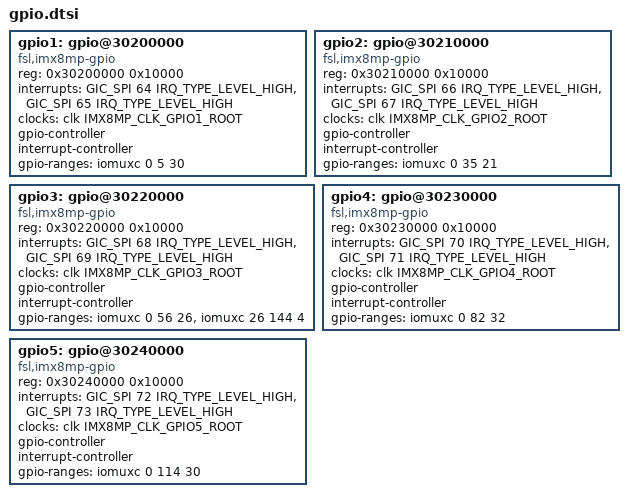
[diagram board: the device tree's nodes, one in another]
			gpio1: gpio@30200000 {
				compatible = "fsl,imx8mp-gpio", "fsl,imx35-gpio";
				reg = <0x30200000 0x10000>;
				interrupts = <GIC_SPI 64 IRQ_TYPE_LEVEL_HIGH>,
					     <GIC_SPI 65 IRQ_TYPE_LEVEL_HIGH>;
				clocks = <&clk IMX8MP_CLK_GPIO1_ROOT>;
				gpio-controller;
				#gpio-cells = <2>;
				interrupt-controller;
				#interrupt-cells = <2>;
				gpio-ranges = <&iomuxc 0 5 30>;
			};

			gpio2: gpio@30210000 {
				compatible = "fsl,imx8mp-gpio", "fsl,imx35-gpio";
				reg = <0x30210000 0x10000>;
				interrupts = <GIC_SPI 66 IRQ_TYPE_LEVEL_HIGH>,
					     <GIC_SPI 67 IRQ_TYPE_LEVEL_HIGH>;
				clocks = <&clk IMX8MP_CLK_GPIO2_ROOT>;
				gpio-controller;
				#gpio-cells = <2>;
				interrupt-controller;
				#interrupt-cells = <2>;
				gpio-ranges = <&iomuxc 0 35 21>;
			};

			gpio3: gpio@30220000 {
				compatible = "fsl,imx8mp-gpio", "fsl,imx35-gpio";
				reg = <0x30220000 0x10000>;
				interrupts = <GIC_SPI 68 IRQ_TYPE_LEVEL_HIGH>,
					     <GIC_SPI 69 IRQ_TYPE_LEVEL_HIGH>;
				clocks = <&clk IMX8MP_CLK_GPIO3_ROOT>;
				gpio-controller;
				#gpio-cells = <2>;
				interrupt-controller;
				#interrupt-cells = <2>;
				gpio-ranges = <&iomuxc 0 56 26>, <&iomuxc 26 144 4>;
			};

			gpio4: gpio@30230000 {
				compatible = "fsl,imx8mp-gpio", "fsl,imx35-gpio";
				reg = <0x30230000 0x10000>;
				interrupts = <GIC_SPI 70 IRQ_TYPE_LEVEL_HIGH>,
					     <GIC_SPI 71 IRQ_TYPE_LEVEL_HIGH>;
				clocks = <&clk IMX8MP_CLK_GPIO4_ROOT>;
				gpio-controller;
				#gpio-cells = <2>;
				interrupt-controller;
				#interrupt-cells = <2>;
				gpio-ranges = <&iomuxc 0 82 32>;
			};

			gpio5: gpio@30240000 {
				compatible = "fsl,imx8mp-gpio", "fsl,imx35-gpio";
				reg = <0x30240000 0x10000>;
				interrupts = <GIC_SPI 72 IRQ_TYPE_LEVEL_HIGH>,
					     <GIC_SPI 73 IRQ_TYPE_LEVEL_HIGH>;
				clocks = <&clk IMX8MP_CLK_GPIO5_ROOT>;
				gpio-controller;
				#gpio-cells = <2>;
				interrupt-controller;
				#interrupt-cells = <2>;
				gpio-ranges = <&iomuxc 0 114 30>;
			};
